# GBA register map
Vendor: Nintendo; File version: 1.0
Game Boy Advance (AGB) memory mapped IO
CPU: ARM7TDMI r0p0, little endian, no MPU, no FPU, 0 interrupt priority bits
Registers are 16-bit, read-write, reset 0x0 unless marked. A register's access mark holds for its fields unless they carry their own. Offsets are from the block's base; lines under a group give offsets from that group; [hi:lo] are bit positions; {n}, {i} and the like mark numbered series; 'fields as' and 'values as' point back to an identical list; <NAME> marks a mode.

## Memory map
0x04000000 PPU size 0x56 — LCD controller, backgrounds, windows and blending
0x04000060 SOUND size 0x48 — PSG channels 1-4 and the two DMA sound FIFOs
0x040000B0 DMA size 0x30 — Four DMA channels; 0 highest priority, 3 lowest
0x04000100 TIMER size 0x10 — Four 16 bit timers, cascadable
0x04000120 SIO size 0x10 — Link port: normal, multiplayer, UART and JOY bus modes
0x04000130 KEYPAD size 0x4 — Buttons; all inputs are active low
0x04000200 SYSTEM size 0x10 — Interrupt control, wait states and power management

## PPU — LCD controller, backgrounds, windows and blending
Base 0x04000000
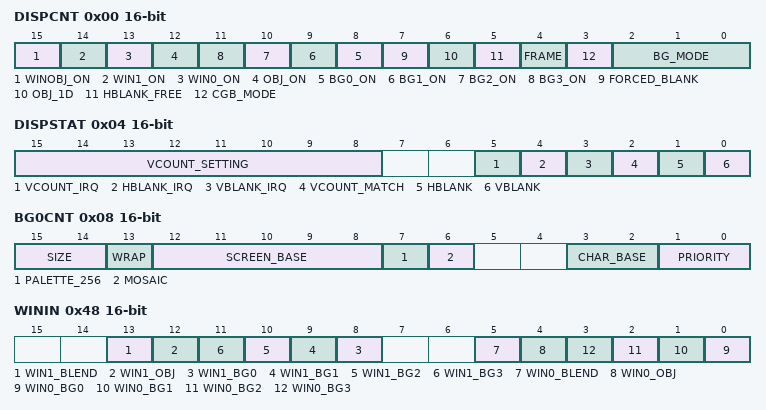
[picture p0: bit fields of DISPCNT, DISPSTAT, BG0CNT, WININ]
0x00 DISPCNT — Display control
  [15] WINOBJ_ON
  [14] WIN1_ON
  [13] WIN0_ON
  [12] OBJ_ON
  [n+8] BG{n}_ON (n=0..3)
  [7] FORCED_BLANK
  [6] OBJ_1D — 1 = linear OBJ tile mapping
  [5] HBLANK_FREE — Allow OAM access during H-blank
  [4] FRAME — Bitmap frame select, modes 4 and 5
  [3] CGB_MODE ro
  [2:0] BG_MODE — 0-2 tiled, 3-5 bitmap
0x02 GREENSWAP — Undocumented green swap
0x04 DISPSTAT — Display status and interrupt select
  [15:8] VCOUNT_SETTING, [5] VCOUNT_IRQ, [4] HBLANK_IRQ, [3] VBLANK_IRQ, [2] VCOUNT_MATCH ro, [1] HBLANK ro, [0] VBLANK ro
0x06 VCOUNT ro — Current scanline, 0-227
0x08 BG0CNT — BG0 control
  [15:14] SIZE
  [13] WRAP — Affine wraparound, BG2 and BG3 only
  [12:8] SCREEN_BASE — Tilemap base, 2 KB units
  [7] PALETTE_256
  [6] MOSAIC
  [3:2] CHAR_BASE — Tile data base, 16 KB units
  [1:0] PRIORITY
{0x8+2i} BG{i}CNT (i=1..3)
{0x10+4i} BG{i}HOFS wo (i=0..3)
{0x12+4i} BG{i}VOFS wo (i=0..3)
0x20 BG2PA wo — BG2 affine dx, 8.8 fixed point
0x22 BG2PB wo
0x24 BG2PC wo
0x26 BG2PD wo
0x28 BG2X 32-bit wo (reset mask 0xFFFF) — BG2 reference X, 20.8 fixed point
0x2C BG2Y 32-bit wo (reset mask 0xFFFF)
0x30 BG3PA wo
0x32 BG3PB wo
0x34 BG3PC wo
0x36 BG3PD wo
0x38 BG3X 32-bit wo (reset mask 0xFFFF)
0x3C BG3Y 32-bit wo (reset mask 0xFFFF)
0x40 WIN0H wo — Window 0 horizontal, [15:8] left, [7:0] right+1
0x42 WIN1H wo
0x44 WIN0V wo
0x46 WIN1V wo
0x48 WININ — Inside-window layer enables
  [13] WIN1_BLEND, [12] WIN1_OBJ, [n+8] WIN1_BG{n} (n=0..3), [5] WIN0_BLEND, [4] WIN0_OBJ, [n] WIN0_BG{n} (n=0..3)
0x4A WINOUT — Outside-window and OBJ-window layer enables
0x4C MOSAIC wo
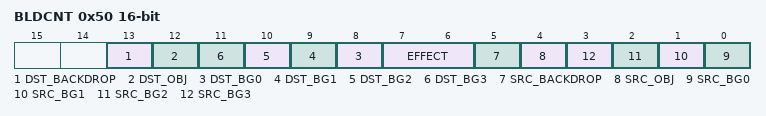
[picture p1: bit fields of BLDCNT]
0x50 BLDCNT — Colour special effects select
  [13] DST_BACKDROP
  [12] DST_OBJ
  [n+8] DST_BG{n} (n=0..3)
  [7:6] EFFECT — 0 none, 1 alpha, 2 brighten, 3 darken
  [5] SRC_BACKDROP
  [4] SRC_OBJ
  [n] SRC_BG{n} (n=0..3)
0x52 BLDALPHA — Alpha coefficients, [4:0] EVA, [12:8] EVB
0x54 BLDY wo — Brightness coefficient EVY, [4:0]

## SOUND — PSG channels 1-4 and the two DMA sound FIFOs
Base 0x04000060
0x00 SOUND1CNT_L — Channel 1 sweep
0x02 SOUND1CNT_H — Channel 1 duty, length, envelope
0x04 SOUND1CNT_X — Channel 1 frequency and control
0x08 SOUND2CNT_L
0x0C SOUND2CNT_H
0x10 SOUND3CNT_L — Channel 3 wave RAM bank control
0x12 SOUND3CNT_H
0x14 SOUND3CNT_X
0x18 SOUND4CNT_L
0x1C SOUND4CNT_H
0x20 SOUNDCNT_L — PSG mixing and volume
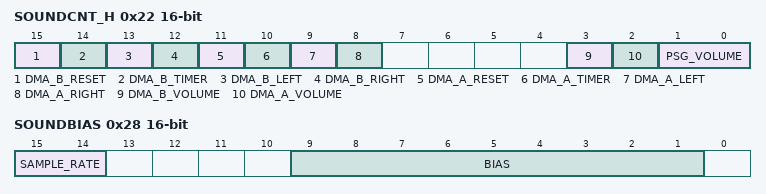
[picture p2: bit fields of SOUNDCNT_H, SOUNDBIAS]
0x22 SOUNDCNT_H — DMA sound mixing and PSG downmix
  [15] DMA_B_RESET
  [14] DMA_B_TIMER
  [13] DMA_B_LEFT
  [12] DMA_B_RIGHT
  [11] DMA_A_RESET
  [10] DMA_A_TIMER
  [9] DMA_A_LEFT
  [8] DMA_A_RIGHT
  [3] DMA_B_VOLUME
  [2] DMA_A_VOLUME
  [1:0] PSG_VOLUME — 0 = 25%, 1 = 50%, 2 = 100%
0x24 SOUNDCNT_X — Master enable and per-channel status
0x28 SOUNDBIAS — DC bias and PWM resampling rate
  [15:14] SAMPLE_RATE — 0 = 9 bit 32 kHz, 3 = 6 bit 262 kHz
  [9:1] BIAS
0x30 WAVE_RAM 32-bit (reset mask 0xFFFF) — Channel 3 wave pattern, 16 bytes, banked
0x40 FIFO_A 32-bit wo (reset mask 0xFFFF)
0x44 FIFO_B 32-bit wo (reset mask 0xFFFF)

## DMA — Four DMA channels; 0 highest priority, 3 lowest
Base 0x040000B0
{0x0+0xC*i} DMA{i}SAD 32-bit wo (reset mask 0xFFFF) (i=0..3)
{0x4+0xC*i} DMA{i}DAD 32-bit wo (reset mask 0xFFFF) (i=0..3)
0x08 DMA0CNT_L wo — Transfer count, 0 means maximum
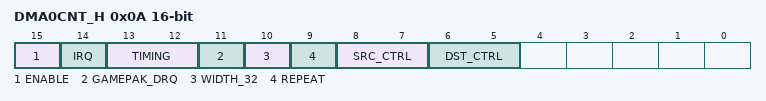
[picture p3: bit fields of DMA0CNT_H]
0x0A DMA0CNT_H — Channel 0 control
  [15] ENABLE
  [14] IRQ
  [13:12] TIMING — 0 now, 1 vblank, 2 hblank, 3 special
  [11] GAMEPAK_DRQ — DMA3 only
  [10] WIDTH_32
  [9] REPEAT
  [8:7] SRC_CTRL
  [6:5] DST_CTRL — 0 inc, 1 dec, 2 fixed, 3 inc+reload
{0x8+0xC*i} DMA{i}CNT_L wo (i=1..3)
{0xA+0xC*i} DMA{i}CNT_H (i=1..3)

## TIMER — Four 16 bit timers, cascadable
Base 0x04000100
0x00 TM0CNT_L — Reads the counter, writes the reload value
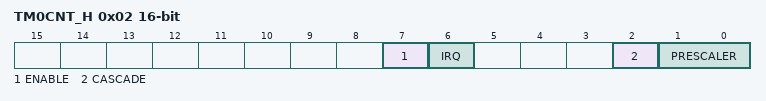
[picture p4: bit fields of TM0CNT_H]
0x02 TM0CNT_H — Timer 0 control
  [7] ENABLE
  [6] IRQ
  [2] CASCADE — Count overflows of the previous timer
  [1:0] PRESCALER — 0 = 1, 1 = 64, 2 = 256, 3 = 1024 cycles
{0x0+4i} TM{i}CNT_L (i=1..3)
{0x2+4i} TM{i}CNT_H (i=1..3)

## SIO — Link port: normal, multiplayer, UART and JOY bus modes
Base 0x04000120
0x00 SIODATA32 32-bit (reset mask 0xFFFF) — Normal mode 32 bit data; also SIOMULTI0/1
0x04 SIOMULTI2
0x06 SIOMULTI3
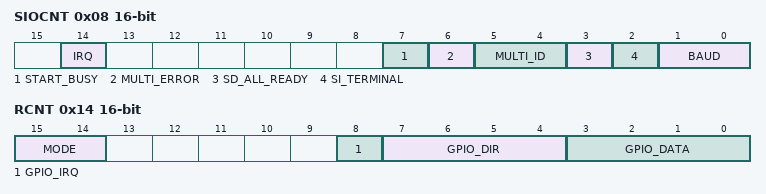
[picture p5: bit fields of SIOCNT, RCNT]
0x08 SIOCNT — Serial control; bit meanings depend on RCNT mode
  [14] IRQ
  [7] START_BUSY
  [6] MULTI_ERROR ro
  [5:4] MULTI_ID ro
  [3] SD_ALL_READY ro
  [2] SI_TERMINAL ro — Multiplayer: 0 = parent
  [1:0] BAUD — 9600, 38400, 57600, 115200
0x0A SIOMLT_SEND — Multiplayer send; SIODATA8 in normal and UART modes
0x14 RCNT — Mode select and general purpose IO on the link pins
  [15:14] MODE — 0/1 serial, 2 general purpose, 3 JOY bus
  [8] GPIO_IRQ
  [7:4] GPIO_DIR
  [3:0] GPIO_DATA

## KEYPAD — Buttons; all inputs are active low
Base 0x04000130
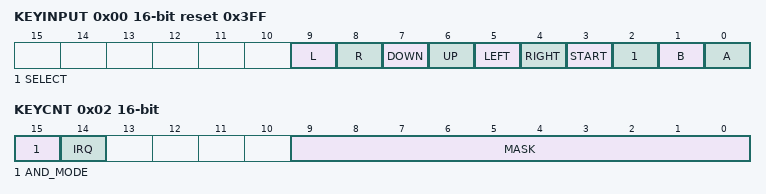
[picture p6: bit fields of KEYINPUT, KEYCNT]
0x00 KEYINPUT ro reset 0x3FF — Button state, 0 = pressed
  [9] L, [8] R, [7] DOWN, [6] UP, [5] LEFT, [4] RIGHT, [3] START, [2] SELECT, [1] B, [0] A
0x02 KEYCNT — Keypad interrupt select
  [15] AND_MODE — 0 = any selected key, 1 = all of them
  [14] IRQ
  [9:0] MASK

## SYSTEM — Interrupt control, wait states and power management
Base 0x04000200
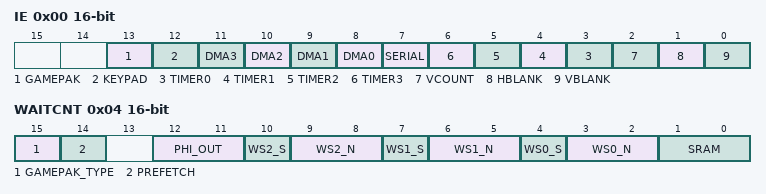
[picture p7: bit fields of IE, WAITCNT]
0x00 IE — Interrupt enable
  [13] GAMEPAK, [12] KEYPAD, [n+8] DMA{n} (n=0..3), [7] SERIAL, [n+3] TIMER{n} (n=0..3), [2] VCOUNT, [1] HBLANK, [0] VBLANK
0x02 IF — Interrupt request flags; write a 1 to acknowledge
0x04 WAITCNT — Game Pak wait states and prefetch
  [15] GAMEPAK_TYPE ro, [14] PREFETCH, [12:11] PHI_OUT, [10] WS2_S, [9:8] WS2_N, [7] WS1_S, [6:5] WS1_N, [4] WS0_S, [3:2] WS0_N, [1:0] SRAM
0x08 IME — Master interrupt enable
  [0] ENABLE
0x100 POSTFLG 8-bit — Post-boot flag; 1 after the BIOS has run once
0x101 HALTCNT 8-bit wo — Write 0 to Halt, 0x80 to Stop
